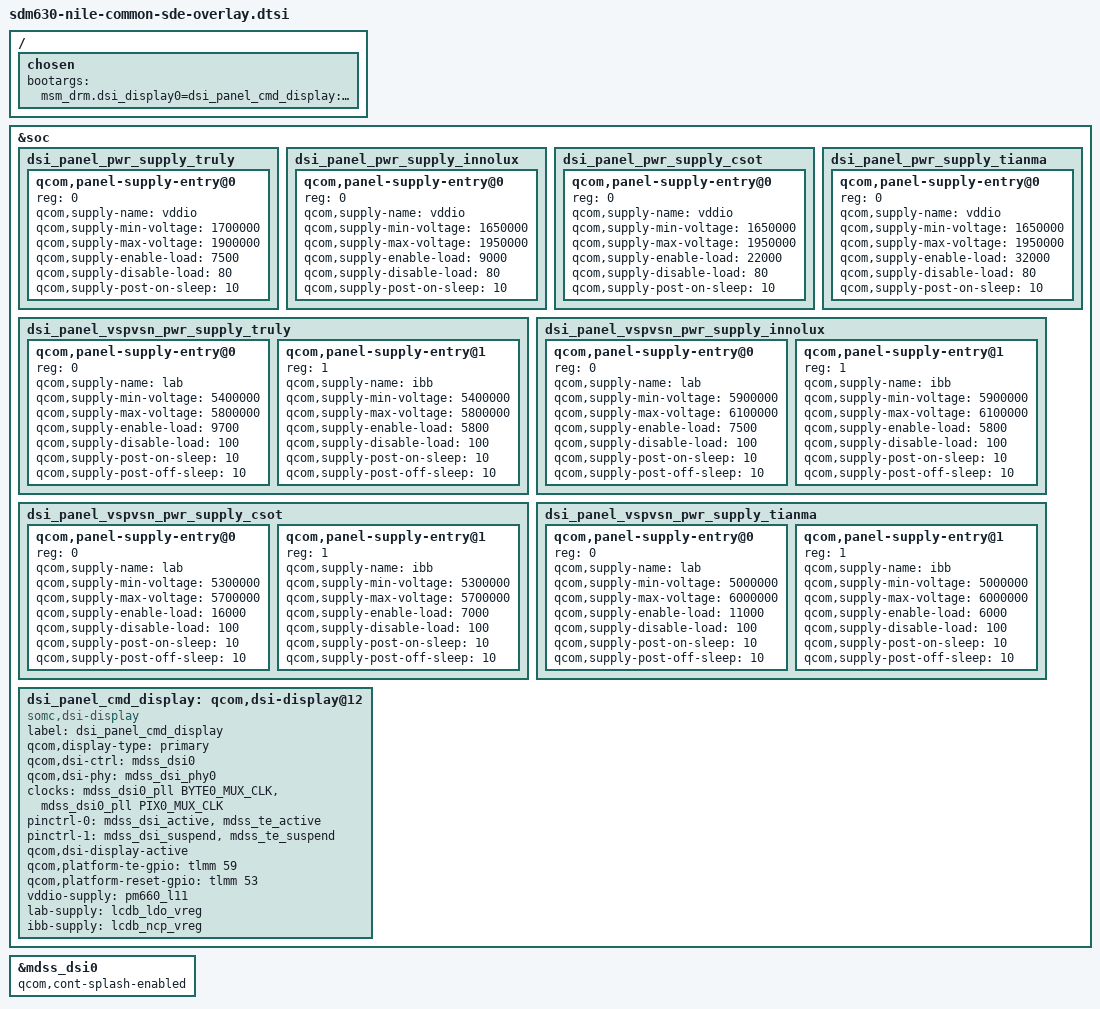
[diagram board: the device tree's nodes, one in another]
#include "sdm630-sde-overlay.dtsi"

/ {
	/* Bad indentation is required. Sorry. */
	chosen {
		bootargs = \
"msm_drm.dsi_display0=dsi_panel_cmd_display:config0";

	};
};

&soc {
	dsi_panel_pwr_supply_truly: dsi_panel_pwr_supply_truly {
		#address-cells = <1>;
		#size-cells = <0>;

		qcom,panel-supply-entry@0 {
			reg = <0>;
			qcom,supply-name = "vddio";
			qcom,supply-min-voltage = <1700000>;
			qcom,supply-max-voltage = <1900000>;
			qcom,supply-enable-load = <7500>;
			qcom,supply-disable-load = <80>;
			qcom,supply-post-on-sleep = <10>;
		};
	};

	dsi_panel_pwr_supply_innolux: dsi_panel_pwr_supply_innolux {
		#address-cells = <1>;
		#size-cells = <0>;

		qcom,panel-supply-entry@0 {
			reg = <0>;
			qcom,supply-name = "vddio";
			qcom,supply-min-voltage = <1650000>;
			qcom,supply-max-voltage = <1950000>;
			qcom,supply-enable-load = <9000>;
			qcom,supply-disable-load = <80>;
			qcom,supply-post-on-sleep = <10>;
		};
	};

	dsi_panel_pwr_supply_csot: dsi_panel_pwr_supply_csot {
		#address-cells = <1>;
		#size-cells = <0>;

		qcom,panel-supply-entry@0 {
			reg = <0>;
			qcom,supply-name = "vddio";
			qcom,supply-min-voltage = <1650000>;
			qcom,supply-max-voltage = <1950000>;
			qcom,supply-enable-load = <22000>;
			qcom,supply-disable-load = <80>;
			qcom,supply-post-on-sleep = <10>;
		};
	};

	dsi_panel_pwr_supply_tianma: dsi_panel_pwr_supply_tianma {
		#address-cells = <1>;
		#size-cells = <0>;

		qcom,panel-supply-entry@0 {
			reg = <0>;
			qcom,supply-name = "vddio";
			qcom,supply-min-voltage = <1650000>;
			qcom,supply-max-voltage = <1950000>;
			qcom,supply-enable-load = <32000>;
			qcom,supply-disable-load = <80>;
			qcom,supply-post-on-sleep = <10>;
		};
	};

	dsi_panel_vspvsn_pwr_supply_truly: dsi_panel_vspvsn_pwr_supply_truly {
		#address-cells = <1>;
		#size-cells = <0>;

		qcom,panel-supply-entry@0 {
			reg = <0>;
			qcom,supply-name = "lab";
			qcom,supply-min-voltage = <5400000>;
			qcom,supply-max-voltage = <5800000>;
			qcom,supply-enable-load = <9700>;
			qcom,supply-disable-load = <100>;
			qcom,supply-post-on-sleep = <10>;
			qcom,supply-post-off-sleep = <10>;
		};

		qcom,panel-supply-entry@1 {
			reg = <1>;
			qcom,supply-name = "ibb";
			qcom,supply-min-voltage = <5400000>;
			qcom,supply-max-voltage = <5800000>;
			qcom,supply-enable-load = <5800>;
			qcom,supply-disable-load = <100>;
			qcom,supply-post-on-sleep = <10>;
			qcom,supply-post-off-sleep = <10>;
		};
	};

	dsi_panel_vspvsn_pwr_supply_innolux: dsi_panel_vspvsn_pwr_supply_innolux {
		#address-cells = <1>;
		#size-cells = <0>;

		qcom,panel-supply-entry@0 {
			reg = <0>;
			qcom,supply-name = "lab";
			qcom,supply-min-voltage = <5900000>;
			qcom,supply-max-voltage = <6100000>;
			qcom,supply-enable-load = <7500>;
			qcom,supply-disable-load = <100>;
			qcom,supply-post-on-sleep = <10>;
			qcom,supply-post-off-sleep = <10>;
		};

		qcom,panel-supply-entry@1 {
			reg = <1>;
			qcom,supply-name = "ibb";
			qcom,supply-min-voltage = <5900000>;
			qcom,supply-max-voltage = <6100000>;
			qcom,supply-enable-load = <5800>;
			qcom,supply-disable-load = <100>;
			qcom,supply-post-on-sleep = <10>;
			qcom,supply-post-off-sleep = <10>;
		};
	};

	dsi_panel_vspvsn_pwr_supply_csot: dsi_panel_vspvsn_pwr_supply_csot {
		#address-cells = <1>;
		#size-cells = <0>;

		qcom,panel-supply-entry@0 {
			reg = <0>;
			qcom,supply-name = "lab";
			qcom,supply-min-voltage = <5300000>;
			qcom,supply-max-voltage = <5700000>;
			qcom,supply-enable-load = <16000>;
			qcom,supply-disable-load = <100>;
			qcom,supply-post-on-sleep = <10>;
			qcom,supply-post-off-sleep = <10>;
		};

		qcom,panel-supply-entry@1 {
			reg = <1>;
			qcom,supply-name = "ibb";
			qcom,supply-min-voltage = <5300000>;
			qcom,supply-max-voltage = <5700000>;
			qcom,supply-enable-load = <7000>;
			qcom,supply-disable-load = <100>;
			qcom,supply-post-on-sleep = <10>;
			qcom,supply-post-off-sleep = <10>;
		};
	};

	dsi_panel_vspvsn_pwr_supply_tianma: dsi_panel_vspvsn_pwr_supply_tianma {
		#address-cells = <1>;
		#size-cells = <0>;

		qcom,panel-supply-entry@0 {
			reg = <0>;
			qcom,supply-name = "lab";
			qcom,supply-min-voltage = <5000000>;
			qcom,supply-max-voltage = <6000000>;
			qcom,supply-enable-load = <11000>;
			qcom,supply-disable-load = <100>;
			qcom,supply-post-on-sleep = <10>;
			qcom,supply-post-off-sleep = <10>;
		};

		qcom,panel-supply-entry@1 {
			reg = <1>;
			qcom,supply-name = "ibb";
			qcom,supply-min-voltage = <5000000>;
			qcom,supply-max-voltage = <6000000>;
			qcom,supply-enable-load = <6000>;
			qcom,supply-disable-load = <100>;
			qcom,supply-post-on-sleep = <10>;
			qcom,supply-post-off-sleep = <10>;
		};
	};


	/* SDE */
	dsi_panel_cmd_display: qcom,dsi-display@12 {
		compatible = "somc,dsi-display";
		label = "dsi_panel_cmd_display";
		qcom,display-type = "primary";

		qcom,dsi-ctrl = <&mdss_dsi0>;
		qcom,dsi-phy = <&mdss_dsi_phy0>;
		clocks = <&mdss_dsi0_pll BYTE0_MUX_CLK>,
			<&mdss_dsi0_pll PIX0_MUX_CLK>;
		clock-names = "src_byte_clk", "src_pixel_clk";

		pinctrl-names = "panel_active", "panel_suspend",
				"sde_touch_active", "sde_touch_suspend";
		pinctrl-0 = <&mdss_dsi_active &mdss_te_active>;
		pinctrl-1 = <&mdss_dsi_suspend &mdss_te_suspend>;

		qcom,dsi-display-active;

		qcom,platform-te-gpio = <&tlmm 59 0>;
		qcom,platform-reset-gpio = <&tlmm 53 0>;
		vddio-supply = <&pm660_l11>;
		lab-supply = <&lcdb_ldo_vreg>;
		ibb-supply = <&lcdb_ncp_vreg>;
	};
};

&mdss_dsi0 {
	qcom,cont-splash-enabled;
};
